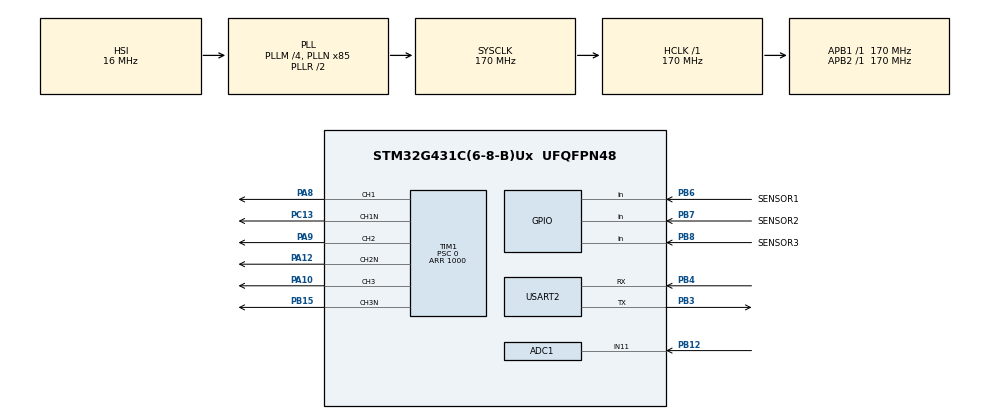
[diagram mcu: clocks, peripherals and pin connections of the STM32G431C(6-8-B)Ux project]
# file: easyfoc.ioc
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ADC1.Channel-0\#ChannelRegularConversion=ADC_CHANNEL_11
ADC1.NbrOfConversionFlag=1
ADC1.OffsetNumber-0\#ChannelRegularConversion=ADC_OFFSET_NONE
ADC1.Rank-0\#ChannelRegularConversion=1
ADC1.SamplingTime-0\#ChannelRegularConversion=ADC_SAMPLETIME_2CYCLES_5
ADC1.master=1
Dma.Request0=USART2_RX
Dma.Request1=USART2_TX
Dma.USART2_RX.0.Direction=DMA_PERIPH_TO_MEMORY
Dma.USART2_RX.0.EventEnable=DISABLE
Dma.USART2_RX.0.Instance=DMA1_Channel1
Dma.USART2_RX.0.MemDataAlignment=DMA_MDATAALIGN_BYTE
Dma.USART2_RX.0.MemInc=DMA_MINC_ENABLE
Dma.USART2_RX.0.Mode=DMA_NORMAL
Dma.USART2_RX.0.PeriphDataAlignment=DMA_PDATAALIGN_BYTE
Dma.USART2_RX.0.PeriphInc=DMA_PINC_DISABLE
Dma.USART2_RX.0.Polarity=HAL_DMAMUX_REQ_GEN_RISING
Dma.USART2_RX.0.Priority=DMA_PRIORITY_LOW
Dma.USART2_RX.0.RequestNumber=1
Dma.USART2_RX.0.SignalID=NONE
Dma.USART2_RX.0.SyncEnable=DISABLE
Dma.USART2_RX.0.SyncPolarity=HAL_DMAMUX_SYNC_NO_EVENT
Dma.USART2_RX.0.SyncRequestNumber=1
Dma.USART2_RX.0.SyncSignalID=NONE
Dma.USART2_TX.1.Direction=DMA_MEMORY_TO_PERIPH
Dma.USART2_TX.1.EventEnable=DISABLE
Dma.USART2_TX.1.Instance=DMA1_Channel2
Dma.USART2_TX.1.MemDataAlignment=DMA_MDATAALIGN_BYTE
Dma.USART2_TX.1.MemInc=DMA_MINC_ENABLE
Dma.USART2_TX.1.Mode=DMA_NORMAL
Dma.USART2_TX.1.PeriphDataAlignment=DMA_PDATAALIGN_BYTE
Dma.USART2_TX.1.PeriphInc=DMA_PINC_DISABLE
Dma.USART2_TX.1.Polarity=HAL_DMAMUX_REQ_GEN_RISING
Dma.USART2_TX.1.Priority=DMA_PRIORITY_LOW
Dma.USART2_TX.1.RequestNumber=1
Dma.USART2_TX.1.SignalID=NONE
Dma.USART2_TX.1.SyncEnable=DISABLE
Dma.USART2_TX.1.SyncPolarity=HAL_DMAMUX_SYNC_NO_EVENT
Dma.USART2_TX.1.SyncRequestNumber=1
Dma.USART2_TX.1.SyncSignalID=NONE
FREERTOS.HEAP_NUMBER=4
FREERTOS.Tasks01=defaultTask,41,512,StartDefaultTask,Default,NULL,Dynamic,NULL,NULL
FREERTOS.configMINIMAL_STACK_SIZE=128
FREERTOS.configTOTAL_HEAP_SIZE=25000
Mcu.Family=STM32G4
Mcu.Name=STM32G431C(6-8-B)Ux
Mcu.Package=UFQFPN48
NVIC.DMA1_Channel1_IRQn=true\:5\:0\:false\:false\:true\:true\:false\:true\:true
NVIC.DMA1_Channel2_IRQn=true\:5\:0\:false\:false\:true\:true\:false\:true\:true
NVIC.PriorityGroup=NVIC_PRIORITYGROUP_4
NVIC.TIM2_IRQn=true\:15\:0\:false\:false\:true\:false\:false\:true\:true
NVIC.TimeBase=TIM2_IRQn
NVIC.TimeBaseIP=TIM2
NVIC.USART2_IRQn=true\:5\:0\:false\:false\:true\:true\:true\:true\:true
PA10.Signal=S_TIM1_CH3
PA12.Mode=PWM Generation2 CH2 CH2N
PA12.Signal=TIM1_CH2N
PA8.Signal=S_TIM1_CH1
PA9.Signal=S_TIM1_CH2
PB12.Mode=IN11-Single-Ended
PB12.Signal=ADC1_IN11
PB15.Mode=PWM Generation3 CH3 CH3N
PB15.Signal=TIM1_CH3N
PB3.Mode=Asynchronous
PB3.Signal=USART2_TX
PB4.Mode=Asynchronous
PB4.Signal=USART2_RX
PB6.GPIO_Label=SENSOR1
PB6.Signal=GPIO_Input
PB7.GPIO_Label=SENSOR2
PB7.Signal=GPIO_Input
PB8-BOOT0.GPIO_Label=SENSOR3
PB8-BOOT0.Signal=GPIO_Input
PC13.Mode=PWM Generation1 CH1 CH1N
PC13.Signal=TIM1_CH1N
PF0-OSC_IN.Mode=HSE-External-Oscillator
PF0-OSC_IN.Signal=RCC_OSC_IN
PF1-OSC_OUT.Mode=HSE-External-Oscillator
PF1-OSC_OUT.Signal=RCC_OSC_OUT
ProjectManager.HeapSize=0x400
ProjectManager.StackSize=0x400
ProjectManager.TargetToolchain=CMake
RCC.ADC12Freq_Value=170000000
RCC.AHBFreq_Value=170000000
RCC.APB1Freq_Value=170000000
RCC.APB1TimFreq_Value=170000000
RCC.APB2Freq_Value=170000000
RCC.APB2TimFreq_Value=170000000
RCC.CortexFreq_Value=170000000
RCC.EXTERNAL_CLOCK_VALUE=12288000
RCC.HCLKFreq_Value=170000000
RCC.HSE_VALUE=8000000
RCC.HSI48_VALUE=48000000
RCC.HSI_VALUE=16000000
RCC.LSE_VALUE=32768
RCC.PLLM=RCC_PLLM_DIV4
RCC.PLLN=85
RCC.SYSCLKFreq_VALUE=170000000
RCC.SYSCLKSource=RCC_SYSCLKSOURCE_PLLCLK
RCC.USBFreq_Value=170000000
RCC.VCOOutputFreq_Value=340000000
SH.S_TIM1_CH1.0=TIM1_CH1,PWM Generation1 CH1 CH1N
SH.S_TIM1_CH2.0=TIM1_CH2,PWM Generation2 CH2 CH2N
SH.S_TIM1_CH3.0=TIM1_CH3,PWM Generation3 CH3 CH3N
TIM1.AutoReloadPreload=TIM_AUTORELOAD_PRELOAD_ENABLE
TIM1.AutomaticOutput=TIM_AUTOMATICOUTPUT_ENABLE
TIM1.Channel-PWM\ Generation1\ CH1\ CH1N=TIM_CHANNEL_1
TIM1.Channel-PWM\ Generation2\ CH2\ CH2N=TIM_CHANNEL_2
TIM1.Channel-PWM\ Generation3\ CH3\ CH3N=TIM_CHANNEL_3
TIM1.ClockDivision=TIM_CLOCKDIVISION_DIV1
TIM1.DeadTime=100
TIM1.OCFastMode_PWM-PWM\ Generation1\ CH1\ CH1N=TIM_OCFAST_ENABLE
TIM1.OCFastMode_PWM-PWM\ Generation2\ CH2\ CH2N=TIM_OCFAST_ENABLE
TIM1.OCFastMode_PWM-PWM\ Generation3\ CH3\ CH3N=TIM_OCFAST_ENABLE
TIM1.OffStateIDLEMode=TIM_OSSI_ENABLE
TIM1.OffStateRunMode=TIM_OSSR_ENABLE
TIM1.PeriodNoDither=1000
TIM1.Prescaler=0
TIM6.AutoReloadPreload=TIM_AUTORELOAD_PRELOAD_ENABLE
TIM6.Prescaler=170-1
USART2.VirtualMode-Asynchronous=VM_ASYNC
VP_FREERTOS_VS_CMSIS_V2.Mode=CMSIS_V2
VP_SYS_VS_DBSignals.Mode=DisableDeadBatterySignals
VP_SYS_VS_tim2.Mode=TIM2
VP_TIM1_VS_ClockSourceINT.Mode=Internal
VP_TIM6_VS_ClockSourceINT.Mode=Enable_Timer
board=custom

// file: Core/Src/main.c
/* USER CODE BEGIN Header */
/**
  ******************************************************************************
  * @file           : main.c
  * @brief          : Main program body
  ******************************************************************************
  * @attention
  *
  * Copyright (c) 2025 STMicroelectronics.
  * All rights reserved.
  *
  * This software is licensed under terms that can be found in the LICENSE file
  * in the root directory of this software component.
  * If no LICENSE file comes with this software, it is provided AS-IS.
  *
  ******************************************************************************
  */
/* USER CODE END Header */
#include "main.h"
#include "cmsis_os.h"
#include "adc.h"
#include "dma.h"
#include "tim.h"
#include "usart.h"
#include "gpio.h"

/* USER CODE BEGIN Includes */
#include "foc.h"
#include "at.h"

/* USER CODE END Includes */

void SystemClock_Config(void);
void MX_FREERTOS_Init(void);

int main(void)
{

  /* MCU Configuration--------------------------------------------------------*/

  /* Reset of all peripherals, Initializes the Flash interface and the Systick. */
  HAL_Init();

  /* Configure the system clock */
  SystemClock_Config();

  /* Initialize all configured peripherals */
  MX_GPIO_Init();
  MX_DMA_Init();
  MX_TIM1_Init();
  MX_ADC1_Init();
  MX_USART2_UART_Init();
  MX_TIM6_Init();
  /* USER CODE BEGIN 2 */
  AT_Init();
  /* USER CODE END 2 */

  /* Init scheduler */
  osKernelInitialize();

  /* Call init function for freertos objects (in cmsis_os2.c) */
  MX_FREERTOS_Init();

  /* Start scheduler */
  osKernelStart();

  /* We should never get here as control is now taken by the scheduler */

  /* Infinite loop */
  while (1)
  {

  }
}

void SystemClock_Config(void)
{
  RCC_OscInitTypeDef RCC_OscInitStruct = {0};
  RCC_ClkInitTypeDef RCC_ClkInitStruct = {0};

  /** Configure the main internal regulator output voltage
  */
  HAL_PWREx_ControlVoltageScaling(PWR_REGULATOR_VOLTAGE_SCALE1_BOOST);

  /** Initializes the RCC Oscillators according to the specified parameters
  * in the RCC_OscInitTypeDef structure.
  */
  RCC_OscInitStruct.OscillatorType = RCC_OSCILLATORTYPE_HSI;
  RCC_OscInitStruct.HSIState = RCC_HSI_ON;
  RCC_OscInitStruct.HSICalibrationValue = RCC_HSICALIBRATION_DEFAULT;
  RCC_OscInitStruct.PLL.PLLState = RCC_PLL_ON;
  RCC_OscInitStruct.PLL.PLLSource = RCC_PLLSOURCE_HSI;
  RCC_OscInitStruct.PLL.PLLM = RCC_PLLM_DIV4;
  RCC_OscInitStruct.PLL.PLLN = 85;
  RCC_OscInitStruct.PLL.PLLP = RCC_PLLP_DIV2;
  RCC_OscInitStruct.PLL.PLLQ = RCC_PLLQ_DIV2;
  RCC_OscInitStruct.PLL.PLLR = RCC_PLLR_DIV2;
  if (HAL_RCC_OscConfig(&RCC_OscInitStruct) != HAL_OK)
  {
    Error_Handler();
  }

  /** Initializes the CPU, AHB and APB buses clocks
  */
  RCC_ClkInitStruct.ClockType = RCC_CLOCKTYPE_HCLK|RCC_CLOCKTYPE_SYSCLK
                              |RCC_CLOCKTYPE_PCLK1|RCC_CLOCKTYPE_PCLK2;
  RCC_ClkInitStruct.SYSCLKSource = RCC_SYSCLKSOURCE_PLLCLK;
  RCC_ClkInitStruct.AHBCLKDivider = RCC_SYSCLK_DIV1;
  RCC_ClkInitStruct.APB1CLKDivider = RCC_HCLK_DIV1;
  RCC_ClkInitStruct.APB2CLKDivider = RCC_HCLK_DIV1;

  if (HAL_RCC_ClockConfig(&RCC_ClkInitStruct, FLASH_LATENCY_4) != HAL_OK)
  {
    Error_Handler();
  }
}

void HAL_TIM_PeriodElapsedCallback(TIM_HandleTypeDef *htim)
{
  if (htim->Instance == TIM2) {
    HAL_IncTick();
  }
}

void Error_Handler(void)
{
  __disable_irq();
  while (1)
  {
  }
}

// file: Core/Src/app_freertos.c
/* USER CODE BEGIN Header */
/**
  ******************************************************************************
  * File Name          : app_freertos.c
  * Description        : Code for freertos applications
  ******************************************************************************
  * @attention
  *
  * Copyright (c) 2025 STMicroelectronics.
  * All rights reserved.
  *
  * This software is licensed under terms that can be found in the LICENSE file
  * in the root directory of this software component.
  * If no LICENSE file comes with this software, it is provided AS-IS.
  *
  ******************************************************************************
  */
/* USER CODE END Header */

#include "FreeRTOS.h"
#include "task.h"
#include "main.h"
#include "cmsis_os.h"

/* USER CODE BEGIN Includes */
#include "foc.h"
#include "adc.h"
#include "at.h"
/* USER CODE END Includes */

/* Definitions for defaultTask */
osThreadId_t defaultTaskHandle;
const osThreadAttr_t defaultTask_attributes = {
  .name = "defaultTask",
  .priority = (osPriority_t) osPriorityHigh1,
  .stack_size = 512 * 4
};

void StartDefaultTask(void *argument);

void MX_FREERTOS_Init(void); /* (MISRA C 2004 rule 8.1) */

void MX_FREERTOS_Init(void) {

  /* Create the thread(s) */
  /* creation of defaultTask */
  defaultTaskHandle = osThreadNew(StartDefaultTask, NULL, &defaultTask_attributes);

  /* USER CODE BEGIN RTOS_THREADS */
  /* add threads, ... */
  foc_init();
  /* USER CODE END RTOS_THREADS */

}

void StartDefaultTask(void *argument)
{
  /* USER CODE BEGIN StartDefaultTask */
  /* Infinite loop */
  for(;;)
  {
    // HAL_ADC_Start(&hadc1);
    // HAL_ADC_PollForConversion(&hadc1, 1);
    // float velocity = HAL_ADC_GetValue(&hadc1) / 4096.0f * 400;
    // set_motor(0.8, 0, velocity);
    // printf("velocity: %f\n", velocity);
    float error = exp_velocity - filtered_velocity;
    float output = exp_velocity + PID(0.8, 0.001, 0, error);
    printf("%f, %f\n", error, output);
    set_motor(q, d, output);
    osDelay(10);
  }
  /* USER CODE END StartDefaultTask */
}
